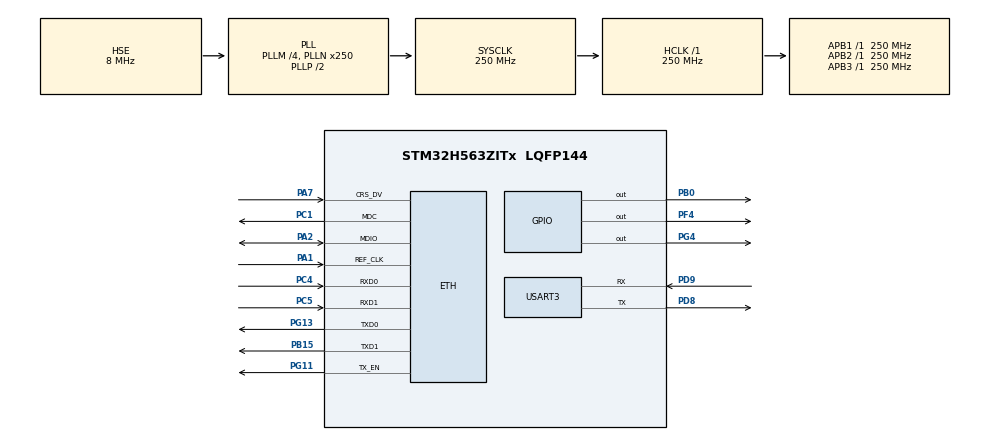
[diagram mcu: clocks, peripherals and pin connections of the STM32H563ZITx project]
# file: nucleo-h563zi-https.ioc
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BOOTPATH.BootPathName=LEGACY
BOOTPATH.UserSelectedBootPath=LEGACY
CORTEX_M33_NS.userName=CORTEX_M33
ETH.MediaInterface=HAL_ETH_RMII_MODE
Mcu.Family=STM32H5
Mcu.Name=STM32H563ZITx
Mcu.Package=LQFP144
NETXDUO.ETH_ON=1
NETXDUO.LAN_8742=1
NETXDUO.NX_APP_IP_INSTANCE_THREAD_SIZE=1024 * 4
NETXDUO.NX_APP_MEM_POOL_SIZE=1024 * 32
NETXDUO.NX_APP_PACKET_POOL_SIZE=10
NETXDUO.NX_DNS_CACHE_ENABLE=true
NETXDUO.NetXDuo_Generate_Init_Code=true
NVIC.ETH_IRQn=true\:0\:0\:false\:false\:true\:false\:true\:true\:true
NVIC.PriorityGroup=NVIC_PRIORITYGROUP_4
NVIC.TIM6_IRQn=true\:15\:0\:false\:false\:true\:false\:false\:true\:true
NVIC.TimeBase=TIM6_IRQn
NVIC.TimeBaseIP=TIM6
NetXDuo.BSP.number=1
NetXDuo0.BSP.STBoard=false
NetXDuo0.BSP.api=BSP_COMPONENT_DRIVER
NetXDuo0.BSP.component=lan8742
NetXDuo0.BSP.instance=lan8742
NetXDuo0.BSP.name=LAN_Component
NetXDuo0.BSP.semaphore=SEMA_lan8742
NetXDuo0.BSP.solution=lan8742
PA1.Mode=RMII
PA1.Signal=ETH_REF_CLK
PA13(JTMS/SWDIO).Mode=Trace_Synchro_4bits_SW
PA13(JTMS/SWDIO).Signal=DEBUG_JTMS-SWDIO
PA14(JTCK/SWCLK).Mode=Trace_Synchro_4bits_SW
PA14(JTCK/SWCLK).Signal=DEBUG_JTCK-SWCLK
PA2.Mode=RMII
PA2.Signal=ETH_MDIO
PA7.Mode=RMII
PA7.Signal=ETH_CRS_DV
PB0.Signal=GPIO_Output
PB15.Mode=RMII
PB15.Signal=ETH_TXD1
PC1.Mode=RMII
PC1.Signal=ETH_MDC
PC4.Mode=RMII
PC4.Signal=ETH_RXD0
PC5.Mode=RMII
PC5.Signal=ETH_RXD1
PD8.Mode=Asynchronous
PD8.Signal=USART3_TX
PD9.Mode=Asynchronous
PD9.Signal=USART3_RX
PE2.Mode=Trace_Synchro_4bits_SW
PE2.Signal=DEBUG_TRACECLK
PE3.Mode=Trace_Synchro_4bits_SW
PE3.Signal=DEBUG_TRACED0
PE4.Mode=Trace_Synchro_4bits_SW
PE4.Signal=DEBUG_TRACED1
PE5.Mode=Trace_Synchro_4bits_SW
PE5.Signal=DEBUG_TRACED2
PE6.Mode=Trace_Synchro_4bits_SW
PE6.Signal=DEBUG_TRACED3
PF4.Signal=GPIO_Output
PG11.Mode=RMII
PG11.Signal=ETH_TX_EN
PG13.Mode=RMII
PG13.Signal=ETH_TXD0
PG4.Signal=GPIO_Output
PH0-OSC_IN(PH0).Mode=HSE-DIG-External-Clock-Source
PH0-OSC_IN(PH0).Signal=RCC_OSC_IN
ProjectManager.HeapSize=0x200
ProjectManager.StackSize=0x400
ProjectManager.TargetToolchain=STM32CubeIDE
RCC.ADCFreq_Value=250000000
RCC.AHBFreq_Value=250000000
RCC.APB1Freq_Value=250000000
RCC.APB1TimFreq_Value=250000000
RCC.APB2Freq_Value=250000000
RCC.APB2TimFreq_Value=250000000
RCC.APB3Freq_Value=250000000
RCC.CSI_VALUE=4000000
RCC.CortexFreq_Value=250000000
RCC.EPOD_VALUE=8000000
RCC.HCLKFreq_Value=250000000
RCC.HSE_VALUE=8000000
RCC.HSI48_VALUE=48000000
RCC.HSI_VALUE=64000000
RCC.LSE_VALUE=32768
RCC.LSIRC_VALUE=32000
RCC.PLLM=4
RCC.PLLN=250
RCC.PLLSourceVirtual=RCC_PLL1_SOURCE_HSE
RCC.SYSCLKFreq_VALUE=250000000
RCC.SYSCLKSource=RCC_SYSCLKSOURCE_PLLCLK
RCC.USBFreq_Value=48000000
RCC.VCOOutputFreq_Value=500000000
THREADX.TX_APP_CREATION=1
THREADX.TX_APP_GENERATE_INIT_CODE=true
THREADX.TX_APP_MEM_POOL_SIZE=1024 * 32
USART3.VirtualMode=VM_ASYNC
VP_BOOTPATH_VS_BOOTPATH.Mode=BP_Activate
VP_CORTEX_M33_NS_VS_Hclk.Mode=Hclk_Mode
VP_ICACHE_VS_ICACHE.Mode=DefaultMode
VP_MEMORYMAP_VS_MEMORYMAP.Mode=CurAppReg
VP_NETXDUO_VS_AddonsOoDHCP.Mode=Addons_DHCP_Client
VP_NETXDUO_VS_AddonsOoDNS.Mode=Addons_DNS
VP_NETXDUO_VS_AddonsOoSNTP.Mode=Addons_SNTP
VP_NETXDUO_VS_AddonsOoWebOoClient.Mode=Addons_Web_Client
VP_NETXDUO_VS_EthernetOoPhyOoInterface.Mode=LAN8742_Phy_Interface
VP_NETXDUO_VS_NXOoCore.Mode=NX_Core
VP_NETXDUO_VS_NetworkOoInterface.Mode=Ethernet_Interface
VP_PWR_VS_DBSignals.Mode=DisableDeadBatterySignals
VP_PWR_VS_LPOM.Mode=PowerOptimisation
VP_PWR_VS_SECSignals.Mode=Security/Privilege
VP_SYS_VS_tim6.Mode=TIM6
VP_THREADX_VS_RTOSJjThreadXJjCoreJjDefault.Mode=Core_Default
board=custom

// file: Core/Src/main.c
/* USER CODE BEGIN Header */
/**
  ******************************************************************************
  * @file           : main.c
  * @brief          : Main program body
  ******************************************************************************
  * @attention
  *
  * Copyright (c) 2024 STMicroelectronics.
  * All rights reserved.
  *
  * This software is licensed under terms that can be found in the LICENSE file
  * in the root directory of this software component.
  * If no LICENSE file comes with this software, it is provided AS-IS.
  *
  ******************************************************************************
  */
/* USER CODE END Header */
#include "app_threadx.h"
#include "main.h"
#include "string.h"

/* USER CODE BEGIN Includes */
#include "printf.h"
/* USER CODE END Includes */

ETH_TxPacketConfigTypeDef TxConfig;
ETH_DMADescTypeDef  DMARxDscrTab[ETH_RX_DESC_CNT]; /* Ethernet Rx DMA Descriptors */
ETH_DMADescTypeDef  DMATxDscrTab[ETH_TX_DESC_CNT]; /* Ethernet Tx DMA Descriptors */

ETH_HandleTypeDef heth;

UART_HandleTypeDef huart3;

void SystemClock_Config(void);
static void MX_GPIO_Init(void);
static void MX_ICACHE_Init(void);
static void MX_ETH_Init(void);
static void MX_USART3_UART_Init(void);

int main(void)
{

  /* MCU Configuration--------------------------------------------------------*/

  /* Reset of all peripherals, Initializes the Flash interface and the Systick. */
  HAL_Init();

  /* Configure the system clock */
  SystemClock_Config();

  /* Initialize all configured peripherals */
  MX_GPIO_Init();
  MX_ICACHE_Init();
  MX_ETH_Init();
  MX_USART3_UART_Init();
  /* USER CODE BEGIN 2 */
  printf("Hello World\n");
  /* USER CODE END 2 */

  MX_ThreadX_Init();

  /* We should never get here as control is now taken by the scheduler */

  /* Infinite loop */
  while (1)
  {

  }
}

void SystemClock_Config(void)
{
  RCC_OscInitTypeDef RCC_OscInitStruct = {0};
  RCC_ClkInitTypeDef RCC_ClkInitStruct = {0};

  /** Configure the main internal regulator output voltage
  */
  __HAL_PWR_VOLTAGESCALING_CONFIG(PWR_REGULATOR_VOLTAGE_SCALE0);

  while(!__HAL_PWR_GET_FLAG(PWR_FLAG_VOSRDY)) {}

  /** Initializes the RCC Oscillators according to the specified parameters
  * in the RCC_OscInitTypeDef structure.
  */
  RCC_OscInitStruct.OscillatorType = RCC_OSCILLATORTYPE_HSE;
  RCC_OscInitStruct.HSEState = RCC_HSE_BYPASS_DIGITAL;
  RCC_OscInitStruct.PLL.PLLState = RCC_PLL_ON;
  RCC_OscInitStruct.PLL.PLLSource = RCC_PLL1_SOURCE_HSE;
  RCC_OscInitStruct.PLL.PLLM = 4;
  RCC_OscInitStruct.PLL.PLLN = 250;
  RCC_OscInitStruct.PLL.PLLP = 2;
  RCC_OscInitStruct.PLL.PLLQ = 2;
  RCC_OscInitStruct.PLL.PLLR = 2;
  RCC_OscInitStruct.PLL.PLLRGE = RCC_PLL1_VCIRANGE_1;
  RCC_OscInitStruct.PLL.PLLVCOSEL = RCC_PLL1_VCORANGE_WIDE;
  RCC_OscInitStruct.PLL.PLLFRACN = 0;
  if (HAL_RCC_OscConfig(&RCC_OscInitStruct) != HAL_OK)
  {
    Error_Handler();
  }

  /** Initializes the CPU, AHB and APB buses clocks
  */
  RCC_ClkInitStruct.ClockType = RCC_CLOCKTYPE_HCLK|RCC_CLOCKTYPE_SYSCLK
                              |RCC_CLOCKTYPE_PCLK1|RCC_CLOCKTYPE_PCLK2
                              |RCC_CLOCKTYPE_PCLK3;
  RCC_ClkInitStruct.SYSCLKSource = RCC_SYSCLKSOURCE_PLLCLK;
  RCC_ClkInitStruct.AHBCLKDivider = RCC_SYSCLK_DIV1;
  RCC_ClkInitStruct.APB1CLKDivider = RCC_HCLK_DIV1;
  RCC_ClkInitStruct.APB2CLKDivider = RCC_HCLK_DIV1;
  RCC_ClkInitStruct.APB3CLKDivider = RCC_HCLK_DIV1;

  if (HAL_RCC_ClockConfig(&RCC_ClkInitStruct, FLASH_LATENCY_5) != HAL_OK)
  {
    Error_Handler();
  }
}

static void MX_ETH_Init(void)
{

   static uint8_t MACAddr[6];

  heth.Instance = ETH;
  MACAddr[0] = 0x00;
  MACAddr[1] = 0x80;
  MACAddr[2] = 0xE1;
  MACAddr[3] = 0x00;
  MACAddr[4] = 0x00;
  MACAddr[5] = 0x00;
  heth.Init.MACAddr = &MACAddr[0];
  heth.Init.MediaInterface = HAL_ETH_RMII_MODE;
  heth.Init.TxDesc = DMATxDscrTab;
  heth.Init.RxDesc = DMARxDscrTab;
  heth.Init.RxBuffLen = 1524;

  if (HAL_ETH_Init(&heth) != HAL_OK)
  {
    Error_Handler();
  }

  memset(&TxConfig, 0 , sizeof(ETH_TxPacketConfigTypeDef));
  TxConfig.Attributes = ETH_TX_PACKETS_FEATURES_CSUM | ETH_TX_PACKETS_FEATURES_CRCPAD;
  TxConfig.ChecksumCtrl = ETH_CHECKSUM_IPHDR_PAYLOAD_INSERT_PHDR_CALC;
  TxConfig.CRCPadCtrl = ETH_CRC_PAD_INSERT;

}

static void MX_ICACHE_Init(void)
{

  /** Enable instruction cache (default 2-ways set associative cache)
  */
  if (HAL_ICACHE_Enable() != HAL_OK)
  {
    Error_Handler();
  }

}

static void MX_USART3_UART_Init(void)
{

  huart3.Instance = USART3;
  huart3.Init.BaudRate = 115200;
  huart3.Init.WordLength = UART_WORDLENGTH_8B;
  huart3.Init.StopBits = UART_STOPBITS_1;
  huart3.Init.Parity = UART_PARITY_NONE;
  huart3.Init.Mode = UART_MODE_TX_RX;
  huart3.Init.HwFlowCtl = UART_HWCONTROL_NONE;
  huart3.Init.OverSampling = UART_OVERSAMPLING_16;
  huart3.Init.OneBitSampling = UART_ONE_BIT_SAMPLE_DISABLE;
  huart3.Init.ClockPrescaler = UART_PRESCALER_DIV1;
  huart3.AdvancedInit.AdvFeatureInit = UART_ADVFEATURE_NO_INIT;
  if (HAL_UART_Init(&huart3) != HAL_OK)
  {
    Error_Handler();
  }
  if (HAL_UARTEx_SetTxFifoThreshold(&huart3, UART_TXFIFO_THRESHOLD_1_8) != HAL_OK)
  {
    Error_Handler();
  }
  if (HAL_UARTEx_SetRxFifoThreshold(&huart3, UART_RXFIFO_THRESHOLD_1_8) != HAL_OK)
  {
    Error_Handler();
  }
  if (HAL_UARTEx_DisableFifoMode(&huart3) != HAL_OK)
  {
    Error_Handler();
  }

}

static void MX_GPIO_Init(void)
{
  GPIO_InitTypeDef GPIO_InitStruct = {0};

  /* GPIO Ports Clock Enable */
  __HAL_RCC_GPIOE_CLK_ENABLE();
  __HAL_RCC_GPIOF_CLK_ENABLE();
  __HAL_RCC_GPIOH_CLK_ENABLE();
  __HAL_RCC_GPIOC_CLK_ENABLE();
  __HAL_RCC_GPIOA_CLK_ENABLE();
  __HAL_RCC_GPIOB_CLK_ENABLE();
  __HAL_RCC_GPIOD_CLK_ENABLE();
  __HAL_RCC_GPIOG_CLK_ENABLE();

  /*Configure GPIO pin Output Level */
  HAL_GPIO_WritePin(GPIOF, GPIO_PIN_4, GPIO_PIN_RESET);

  /*Configure GPIO pin Output Level */
  HAL_GPIO_WritePin(GPIOB, GPIO_PIN_0, GPIO_PIN_RESET);

  /*Configure GPIO pin Output Level */
  HAL_GPIO_WritePin(GPIOG, GPIO_PIN_4, GPIO_PIN_RESET);

  /*Configure GPIO pin : PF4 */
  GPIO_InitStruct.Pin = GPIO_PIN_4;
  GPIO_InitStruct.Mode = GPIO_MODE_OUTPUT_PP;
  GPIO_InitStruct.Pull = GPIO_NOPULL;
  GPIO_InitStruct.Speed = GPIO_SPEED_FREQ_LOW;
  HAL_GPIO_Init(GPIOF, &GPIO_InitStruct);

  /*Configure GPIO pin : PB0 */
  GPIO_InitStruct.Pin = GPIO_PIN_0;
  GPIO_InitStruct.Mode = GPIO_MODE_OUTPUT_PP;
  GPIO_InitStruct.Pull = GPIO_NOPULL;
  GPIO_InitStruct.Speed = GPIO_SPEED_FREQ_LOW;
  HAL_GPIO_Init(GPIOB, &GPIO_InitStruct);

  /*Configure GPIO pin : PG4 */
  GPIO_InitStruct.Pin = GPIO_PIN_4;
  GPIO_InitStruct.Mode = GPIO_MODE_OUTPUT_PP;
  GPIO_InitStruct.Pull = GPIO_NOPULL;
  GPIO_InitStruct.Speed = GPIO_SPEED_FREQ_LOW;
  HAL_GPIO_Init(GPIOG, &GPIO_InitStruct);

}

/* USER CODE BEGIN 4 */
void _putchar(char character)
{
  HAL_UART_Transmit(&huart3, (uint8_t *)&character, 1, 1000);
}
/* USER CODE END 4 */

void HAL_TIM_PeriodElapsedCallback(TIM_HandleTypeDef *htim)
{
  if (htim->Instance == TIM6) {
    HAL_IncTick();
  }
}

void Error_Handler(void)
{
  __disable_irq();
  while (1)
  {
  }
}
